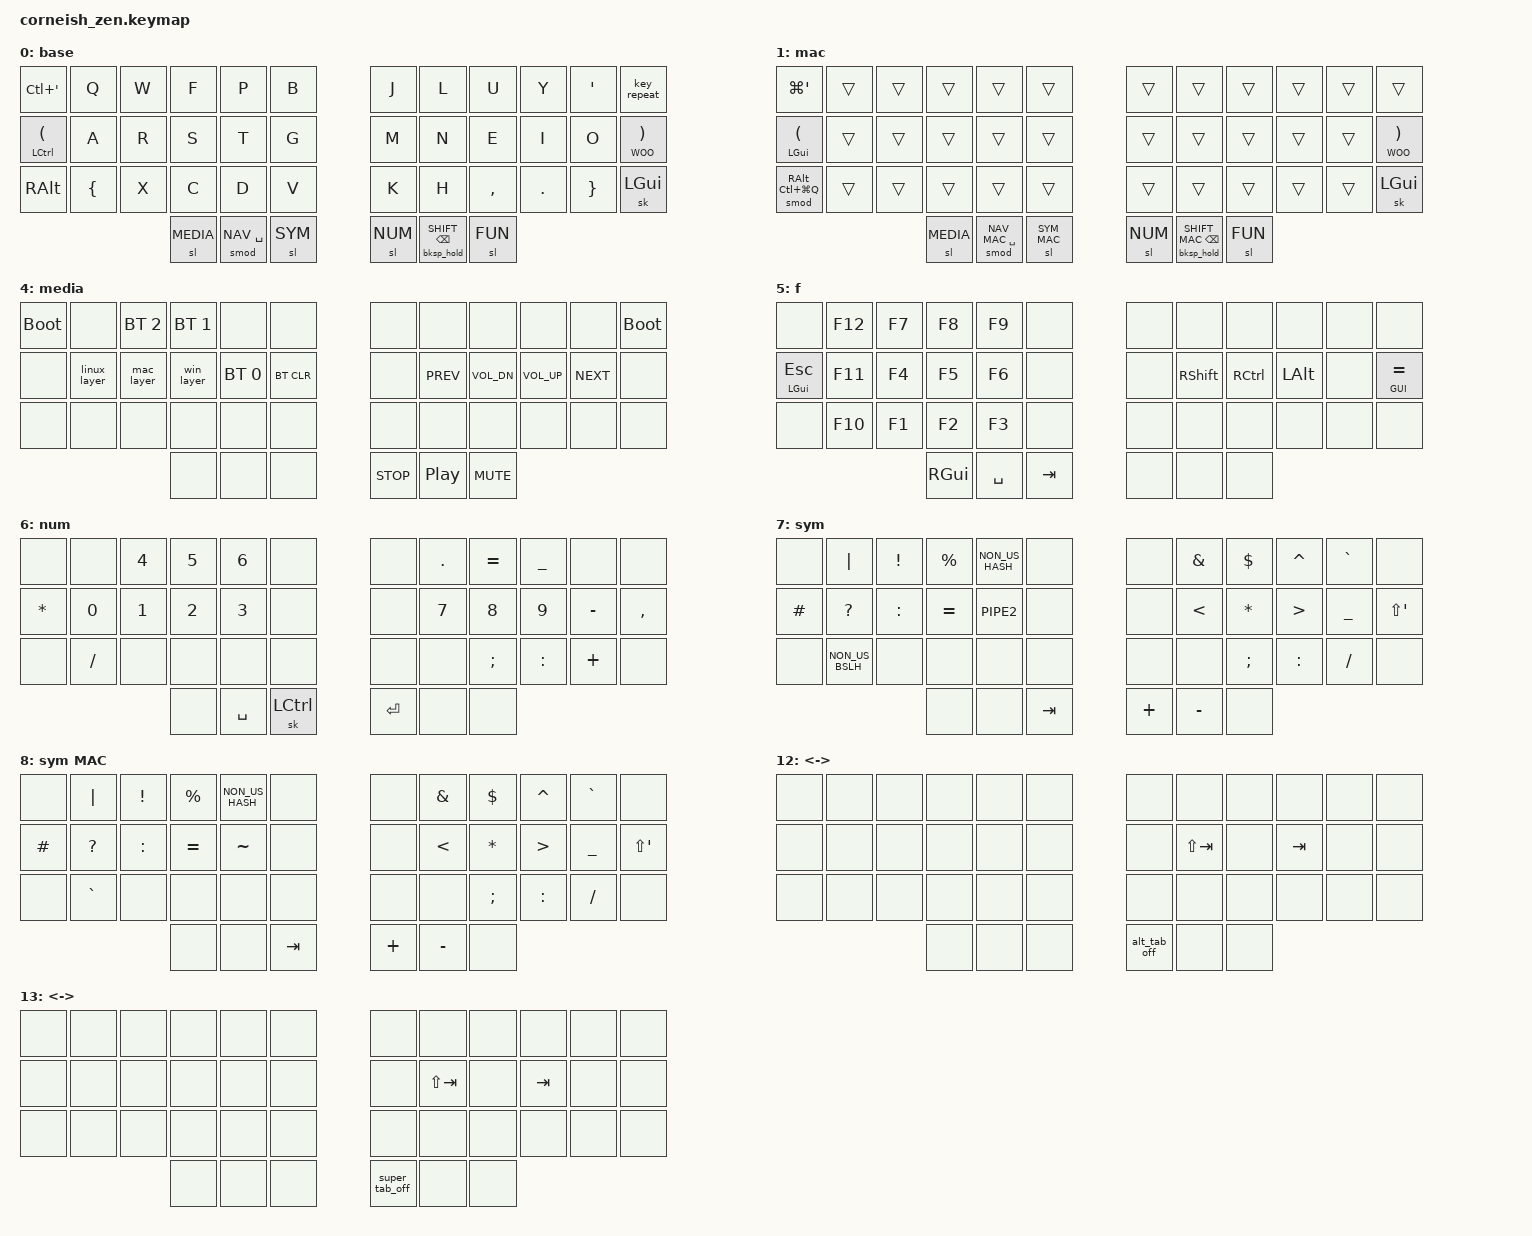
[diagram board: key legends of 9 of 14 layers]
/*
*
* Copyright (c) 2021 Darryl deHaan
* SPDX-License-Identifier: MIT
*
*/

#include <behaviors.dtsi>
#include <dt-bindings/zmk/keys.h>
#include <dt-bindings/zmk/bt.h>

#include "layers.dtsi"
#include "combos.dtsi"
#include "behaviors.dtsi"
#include "macros.dtsi"

/ {
    chosen {
        zmk,matrix_transform = &default_transform;
    };
};

#define HYPER LS(LC(LA(LGUI)))
#define MEH   LS(LC(LALT))
#define WOO   LC(LA(LGUI)) // I don't know what this is called

&caps_word {
    continue-list = <UNDERSCORE MINUS BACKSPACE N1 N2 N3 N4 N5 N6 N7 N8 N9 N0>;
};

/ {
    keymap {
        compatible = "zmk,keymap";

        base_layer {
            label = "base";
            bindings = <
// ╭─────────────────┬─────────────────┬─────────────────┬─────────────────┬─────────────────┬─────────────────╮   ╭─────────────────┬─────────────────┬─────────────────┬─────────────────┬─────────────────┬─────────────────╮
     &kp LC(SQT)       &kp Q           &kp W             &kp F             &kp P             &kp B                 &kp J             &kp L             &kp U             &kp Y             &kp SQT           &key_repeat
// ├─────────────────┼─────────────────┼─────────────────┼─────────────────┼─────────────────┼─────────────────┤   ├─────────────────┼─────────────────┼─────────────────┼─────────────────┼─────────────────┼─────────────────┤
     &hmod LCTRL LPAR  &kp A             &kp R             &kp S             &kp T             &kp G                 &kp M             &kp N             &kp E             &kp I             &kp O             &hmod WOO RPAR
// ├─────────────────┼─────────────────┼─────────────────┼─────────────────┼─────────────────┼─────────────────┤   ├─────────────────┼─────────────────┼─────────────────┼─────────────────┼─────────────────┼─────────────────┤
     &kp RALT          &kp LBRC          &kp X             &kp C             &kp D             &kp V                 &kp K             &kp H             &kp COMMA         &kp DOT           &kp RBRC          &sk LGUI
// ╰─────────────────┴─────────────────┴─────────────────┼─────────────────┼─────────────────┼─────────────────┤   ├─────────────────┼─────────────────┼─────────────────┼─────────────────┴─────────────────┴─────────────────╯
                                                           &sl MEDIA         &smod NAV SPACE   &sl SYM               &sl NUM        &bksp_hold SHIFT BKSP  &sl FUN
//                                                       ╰─────────────────┴─────────────────┴─────────────────╯   ╰─────────────────┴─────────────────┴─────────────────╯
            >;
        };
        
        base_layer_mac {
            label = "mac";
            bindings = <
// ╭─────────────────┬─────────────────┬─────────────────┬─────────────────┬─────────────────┬─────────────────╮   ╭─────────────────┬─────────────────┬─────────────────┬─────────────────┬─────────────────┬─────────────────╮
     &kp LG(SQT)       &trans          &trans            &trans            &trans            &trans                &trans            &trans            &trans            &trans            &trans            &trans
// ├─────────────────┼─────────────────┼─────────────────┼─────────────────┼─────────────────┼─────────────────┤   ├─────────────────┼─────────────────┼─────────────────┼─────────────────┼─────────────────┼─────────────────┤
     &hmod LGUI LPAR   &trans            &trans            &trans            &trans            &trans                &trans            &trans            &trans            &trans            &trans            &hmod WOO RPAR 
// ├─────────────────┼─────────────────┼─────────────────┼─────────────────┼─────────────────┼─────────────────┤   ├─────────────────┼─────────────────┼─────────────────┼─────────────────┼─────────────────┼─────────────────┤
 &smod RALT LC(LG(Q))  &trans            &trans            &trans            &trans            &trans                &trans            &trans            &trans            &trans            &trans            &sk LGUI
// ╰─────────────────┴─────────────────┴─────────────────┼─────────────────┼─────────────────┼─────────────────┤   ├─────────────────┼─────────────────┼─────────────────┼─────────────────┴─────────────────┴─────────────────╯
                                                           &sl MEDIA       &smod NAV_MAC SPACE  &sl SYM_MAC          &sl NUM      &bksp_hold SHIFT_MAC BKSP  &sl FUN
//                                                       ╰─────────────────┴─────────────────┴─────────────────╯   ╰─────────────────┴─────────────────┴─────────────────╯
            >;
        };
        
        shift_layer {
            label = "shift";
            bindings = <
// ╭─────────────────┬─────────────────┬─────────────────┬─────────────────┬─────────────────┬─────────────────╮   ╭─────────────────┬─────────────────┬─────────────────┬─────────────────┬─────────────────┬─────────────────╮
     &kp LC(LA(LG(SQT))) &kp LS(Q)         &kp LS(W)         &kp LS(F)         &kp LS(P)         &kp LS(B)             &kp LS(J)         &kp LS(L)         &kp LS(U)         &kp LS(Y)         &kp AT            &key_repeat
// ├─────────────────┼─────────────────┼─────────────────┼─────────────────┼─────────────────┼─────────────────┤   ├─────────────────┼─────────────────┼─────────────────┼─────────────────┼─────────────────┼─────────────────┤
     &kp GRAV          &kp LS(A)         &kp LS(R)         &kp LS(S)         &kp LS(T)         &kp LS(G)             &kp LS(M)         &kp LS(N)         &kp LS(E)         &kp LS(I)         &kp LS(O)         &kp EQUAL
// ├─────────────────┼─────────────────┼─────────────────┼─────────────────┼─────────────────┼─────────────────┤   ├─────────────────┼─────────────────┼─────────────────┼─────────────────┼─────────────────┼─────────────────┤
     &none             &kp LBKT          &kp LS(X)         &kp LS(C)         &kp LS(D)         &kp LS(V)             &kp LS(K)         &kp LS(H)         &kp SEMI          &kp COLON         &kp RBKT          &none
// ╰─────────────────┴─────────────────┴─────────────────┼─────────────────┼─────────────────┼─────────────────┤   ├─────────────────┼─────────────────┼─────────────────┼─────────────────┴─────────────────┴─────────────────╯
                                                           &sl MEDIA         &kp SPACE         &kp MINUS             &kp LS(RET)       &sk LSHIFT        &sl FUN
//                                                       ╰─────────────────┴─────────────────┴─────────────────╯   ╰─────────────────┴─────────────────┴─────────────────╯
            >;
        };

        shift_layer_mac {
            label = "shift MAC";
            bindings = <
// ╭─────────────────┬─────────────────┬─────────────────┬─────────────────┬─────────────────┬─────────────────╮   ╭─────────────────┬─────────────────┬─────────────────┬─────────────────┬─────────────────┬─────────────────╮
     &kp LC(LA(LG(SQT))) &kp LS(Q)         &kp LS(W)         &kp LS(F)         &kp LS(P)         &kp LS(B)             &kp LS(J)         &kp LS(L)         &kp LS(U)         &kp LS(Y)         &kp AT            &key_repeat
// ├─────────────────┼─────────────────┼─────────────────┼─────────────────┼─────────────────┼─────────────────┤   ├─────────────────┼─────────────────┼─────────────────┼─────────────────┼─────────────────┼─────────────────┤
     &kp NON_US_BSLH   &kp LS(A)         &kp LS(R)         &kp LS(S)         &kp LS(T)         &kp LS(G)             &kp LS(M)         &kp LS(N)         &kp LS(E)         &kp LS(I)         &kp LS(O)         &kp EQUAL
// ├─────────────────┼─────────────────┼─────────────────┼─────────────────┼─────────────────┼─────────────────┤   ├─────────────────┼─────────────────┼─────────────────┼─────────────────┼─────────────────┼─────────────────┤
     &none             &kp LBKT          &kp LS(X)         &kp LS(C)         &kp LS(D)         &kp LS(V)             &kp LS(K)         &kp LS(H)         &kp SEMI          &kp COLON         &kp RBKT          &none
// ╰─────────────────┴─────────────────┴─────────────────┼─────────────────┼─────────────────┼─────────────────┤   ├─────────────────┼─────────────────┼─────────────────┼─────────────────┴─────────────────┴─────────────────╯
                                                           &sl MEDIA         &kp SPACE         &kp MINUS             &kp LS(RET)       &sk LSHIFT        &sl FUN
//                                                       ╰─────────────────┴─────────────────┴─────────────────╯   ╰─────────────────┴─────────────────┴─────────────────╯
            >;
        };

        media_layer {
            label = "media";
            bindings = <
// ╭─────────────────┬─────────────────┬─────────────────┬─────────────────┬─────────────────┬─────────────────╮   ╭─────────────────┬─────────────────┬─────────────────┬─────────────────┬─────────────────┬─────────────────╮
     &bootloader       &none             &bt BT_SEL 2      &bt BT_SEL 1      &none             &none                 &none             &none             &none             &none             &none             &bootloader
// ├─────────────────┼─────────────────┼─────────────────┼─────────────────┼─────────────────┼─────────────────┤   ├─────────────────┼─────────────────┼─────────────────┼─────────────────┼─────────────────┼─────────────────┤
     &none             &linux_layer      &mac_layer        &win_layer        &bt BT_SEL 0      &bt BT_CLR            &none             &kp C_PREV        &kp C_VOL_DN      &kp C_VOL_UP      &kp C_NEXT        &none
// ├─────────────────┼─────────────────┼─────────────────┼─────────────────┼─────────────────┼─────────────────┤   ├─────────────────┼─────────────────┼─────────────────┼─────────────────┼─────────────────┼─────────────────┤
     &none             &none             &none             &none             &none             &none                 &none             &none             &none             &none             &none             &none
// ╰─────────────────┴─────────────────┴─────────────────┼─────────────────┼─────────────────┼─────────────────┤   ├─────────────────┼─────────────────┼─────────────────┼─────────────────┴─────────────────┴─────────────────╯
                                                           &none             &none             &none                 &kp C_STOP        &kp C_PLAY_PAUSE  &kp C_MUTE
//                                                       ╰─────────────────┴─────────────────┴─────────────────╯   ╰─────────────────┴─────────────────┴─────────────────╯
            >;
        };

        fun_layer {
            label = "f";
            bindings = <
// ╭─────────────────┬─────────────────┬─────────────────┬─────────────────┬─────────────────┬─────────────────╮   ╭─────────────────┬─────────────────┬─────────────────┬─────────────────┬─────────────────┬─────────────────╮
     &none             &kp F12           &kp F7            &kp F8            &kp F9            &none                 &none             &none             &none             &none             &none             &none
// ├─────────────────┼─────────────────┼─────────────────┼─────────────────┼─────────────────┼─────────────────┤   ├─────────────────┼─────────────────┼─────────────────┼─────────────────┼─────────────────┼─────────────────┤
     &mt LGUI ESC      &kp F11           &kp F4            &kp F5            &kp F6            &none                 &none             &kp RSHIFT        &kp RCTRL         &kp LALT          &none             &mt GUI EQUAL
// ├─────────────────┼─────────────────┼─────────────────┼─────────────────┼─────────────────┼─────────────────┤   ├─────────────────┼─────────────────┼─────────────────┼─────────────────┼─────────────────┼─────────────────┤
     &none             &kp F10           &kp F1            &kp F2            &kp F3            &none                 &none             &none             &none             &none             &none             &none
// ╰─────────────────┴─────────────────┴─────────────────┼─────────────────┼─────────────────┼─────────────────┤   ├─────────────────┼─────────────────┼─────────────────┼─────────────────┴─────────────────┴─────────────────╯
                                                           &kp RGUI          &kp SPACE         &kp TAB               &none             &none             &none
//                                                       ╰─────────────────┴─────────────────┴─────────────────╯   ╰─────────────────┴─────────────────┴─────────────────╯
            >;
        };


        num {
            label = "num";
            bindings = <
// ╭─────────────────┬─────────────────┬─────────────────┬─────────────────┬─────────────────┬─────────────────╮   ╭─────────────────┬─────────────────┬─────────────────┬─────────────────┬─────────────────┬─────────────────╮
     &none             &none             &kp N4            &kp N5            &kp N6            &none                 &none             &kp DOT           &kp EQUAL         &kp UNDERSCORE    &none             &none
// ├─────────────────┼─────────────────┼─────────────────┼─────────────────┼─────────────────┼─────────────────┤   ├─────────────────┼─────────────────┼─────────────────┼─────────────────┼─────────────────┼─────────────────┤
     &kp ASTRK         &kp N0            &kp N1            &kp N2            &kp N3            &none                 &none             &kp N7            &kp N8            &kp N9            &kp MINUS         &kp COMMA
// ├─────────────────┼─────────────────┼─────────────────┼─────────────────┼─────────────────┼─────────────────┤   ├─────────────────┼─────────────────┼─────────────────┼─────────────────┼─────────────────┼─────────────────┤
     &none             &kp FSLH          &none             &none             &none             &none                 &none             &none             &kp SEMI          &kp COLON         &kp PLUS          &none
// ╰─────────────────┴─────────────────┴─────────────────┼─────────────────┼─────────────────┼─────────────────┤   ├─────────────────┼─────────────────┼─────────────────┼─────────────────┴─────────────────┴─────────────────╯
                                                           &none             &kp SPACE         &sk LCTRL             &kp RET           &none             &none
//                                                       ╰─────────────────┴─────────────────┴─────────────────╯   ╰─────────────────┴─────────────────┴─────────────────╯
            >;
        };

        sym {
            label = "sym";
            bindings = <
// ╭─────────────────┬─────────────────┬─────────────────┬─────────────────┬─────────────────┬─────────────────╮   ╭─────────────────┬─────────────────┬─────────────────┬─────────────────┬─────────────────┬─────────────────╮
     &none             &kp PIPE          &kp EXCL          &kp PERCENT       &kp NON_US_HASH   &none                 &none             &kp AMPS          &kp DOLLAR        &kp CARET         &kp GRAV          &none
// ├─────────────────┼─────────────────┼─────────────────┼─────────────────┼─────────────────┼─────────────────┤   ├─────────────────┼─────────────────┼─────────────────┼─────────────────┼─────────────────┼─────────────────┤
     &kp HASH          &kp QUESTION      &kp COLON         &kp EQUAL         &kp PIPE2         &none                 &none             &kp LT            &kp ASTRK         &kp GT            &kp UNDERSCORE    &kp LS(SQT)
// ├─────────────────┼─────────────────┼─────────────────┼─────────────────┼─────────────────┼─────────────────┤   ├─────────────────┼─────────────────┼─────────────────┼─────────────────┼─────────────────┼─────────────────┤
     &none             &kp NON_US_BSLH   &none             &none             &none             &none                 &none             &none             &kp SEMI          &kp COLON         &kp FSLH          &none
// ╰─────────────────┴─────────────────┴─────────────────┼─────────────────┼─────────────────┼─────────────────┤   ├─────────────────┼─────────────────┼─────────────────┼─────────────────┴─────────────────┴─────────────────╯
                                                           &none             &none             &kp TAB               &kp PLUS          &kp MINUS         &none
//                                                       ╰─────────────────┴─────────────────┴─────────────────╯   ╰─────────────────┴─────────────────┴─────────────────╯
            >;
        };

        sym_mac {
            label = "sym MAC";
            bindings = <
// ╭─────────────────┬─────────────────┬─────────────────┬─────────────────┬─────────────────┬─────────────────╮   ╭─────────────────┬─────────────────┬─────────────────┬─────────────────┬─────────────────┬─────────────────╮
     &none             &kp PIPE          &kp EXCL          &kp PERCENT       &kp NON_US_HASH   &none                 &none             &kp AMPS          &kp DOLLAR        &kp CARET         &kp GRAV          &none
// ├─────────────────┼─────────────────┼─────────────────┼─────────────────┼─────────────────┼─────────────────┤   ├─────────────────┼─────────────────┼─────────────────┼─────────────────┼─────────────────┼─────────────────┤
     &kp HASH          &kp QUESTION      &kp COLON         &kp EQUAL         &kp TILDE         &none                 &none             &kp LT            &kp ASTRK         &kp GT            &kp UNDERSCORE    &kp LS(SQT)
// ├─────────────────┼─────────────────┼─────────────────┼─────────────────┼─────────────────┼─────────────────┤   ├─────────────────┼─────────────────┼─────────────────┼─────────────────┼─────────────────┼─────────────────┤
     &none             &kp GRAV          &none             &none             &none             &none                 &none             &none             &kp SEMI          &kp COLON         &kp FSLH          &none
// ╰─────────────────┴─────────────────┴─────────────────┼─────────────────┼─────────────────┼─────────────────┤   ├─────────────────┼─────────────────┼─────────────────┼─────────────────┴─────────────────┴─────────────────╯
                                                           &none             &none             &kp TAB               &kp PLUS          &kp MINUS         &none
//                                                       ╰─────────────────┴─────────────────┴─────────────────╯   ╰─────────────────┴─────────────────┴─────────────────╯
            >;
        };

        nav {
            label = "nav";
            bindings = <
// ╭─────────────────┬─────────────────┬─────────────────┬─────────────────┬─────────────────┬─────────────────╮   ╭─────────────────┬─────────────────┬─────────────────┬─────────────────┬─────────────────┬─────────────────╮
     &none             &none             &none             &kp HOME          &kp END           &none                 &none             &kp F12           &kp UP            &kp LC(F12)       &none             &none
// ├─────────────────┼─────────────────┼─────────────────┼─────────────────┼─────────────────┼─────────────────┤   ├─────────────────┼─────────────────┼─────────────────┼─────────────────┼─────────────────┼─────────────────┤
     &none             &kp LC(TAB)       &kp LA(TAB)       &kp PG_UP         &kp PG_DN         &none                 &none             &kp LEFT          &kp DOWN          &kp RIGHT         &kp DEL           &none
// ├─────────────────┼─────────────────┼─────────────────┼─────────────────┼─────────────────┼─────────────────┤   ├─────────────────┼─────────────────┼─────────────────┼─────────────────┼─────────────────┼─────────────────┤
     &none             &none             &none             &none             &none             &none                 &none             &none             &none             &none             &kp DEL           &none
// ╰─────────────────┴─────────────────┴─────────────────┼─────────────────┼─────────────────┼─────────────────┤   ├─────────────────┼─────────────────┼─────────────────┼─────────────────┴─────────────────┴─────────────────╯
                                                           &none             &none             &none                 &alt_tab_on       &kp LG(LC(LA(SPACE)))     &caps_word
//                                                       ╰─────────────────┴─────────────────┴─────────────────╯   ╰─────────────────┴─────────────────┴─────────────────╯
            >;
        };
        
        nav_mac {
            label = "nav MAC";
            bindings = <
// ╭─────────────────┬─────────────────┬─────────────────┬─────────────────┬─────────────────┬─────────────────╮   ╭─────────────────┬─────────────────┬─────────────────┬─────────────────┬─────────────────┬─────────────────╮
     &none             &none             &none             &kp HOME          &kp END           &none                 &none             &kp F12           &kp UP            &kp LG(F12)       &none             &none
// ├─────────────────┼─────────────────┼─────────────────┼─────────────────┼─────────────────┼─────────────────┤   ├─────────────────┼─────────────────┼─────────────────┼─────────────────┼─────────────────┼─────────────────┤
     &none           &kp LG(NON_US_BSLH) &kp LG(TAB)       &kp PG_UP         &kp PG_DN         &none                 &none             &kp LEFT          &kp DOWN          &kp RIGHT         &kp DEL           &none
// ├─────────────────┼─────────────────┼─────────────────┼─────────────────┼─────────────────┼─────────────────┤   ├─────────────────┼─────────────────┼─────────────────┼─────────────────┼─────────────────┼─────────────────┤
     &none             &none             &none             &none             &none             &none                 &none             &none             &none             &none             &kp DEL           &none
// ╰─────────────────┴─────────────────┴─────────────────┼─────────────────┼─────────────────┼─────────────────┤   ├─────────────────┼─────────────────┼─────────────────┼─────────────────┴─────────────────┴─────────────────╯
                                                           &none             &none             &none                 &super_tab_on     &kp LG(LC(LA(SPACE)))     &caps_word
//                                                       ╰─────────────────┴─────────────────┴─────────────────╯   ╰─────────────────┴─────────────────┴─────────────────╯
            >;
        };
        
        fn {
            label = "fn";
            bindings = <
// ╭─────────────────┬─────────────────┬─────────────────┬─────────────────┬─────────────────┬─────────────────╮   ╭─────────────────┬─────────────────┬─────────────────┬─────────────────┬─────────────────┬─────────────────╮
     &none             &none             &kp F5            &kp F8            &none             &none                 &none             &none             &none             &none             &none             &none
// ├─────────────────┼─────────────────┼─────────────────┼─────────────────┼─────────────────┼─────────────────┤   ├─────────────────┼─────────────────┼─────────────────┼─────────────────┼─────────────────┼─────────────────┤
     &none             &none             &kp F10           &kp F2            &kp F12           &none                 &none             &kp LC(LA(LG(0))) &kp LC(LA(LG(1))) &kp LC(LA(LG(3))) &none             &none
// ├─────────────────┼─────────────────┼─────────────────┼─────────────────┼─────────────────┼─────────────────┤   ├─────────────────┼─────────────────┼─────────────────┼─────────────────┼─────────────────┼─────────────────┤
     &none             &none             &none             &none             &none             &none                 &none             &none             &none             &none             &none             &none
// ╰─────────────────┴─────────────────┴─────────────────┼─────────────────┼─────────────────┼─────────────────┤   ├─────────────────┼─────────────────┼─────────────────┼─────────────────┴─────────────────┴─────────────────╯
                                                           &none             &none             &none                 &none             &none             &none
//                                                       ╰─────────────────┴─────────────────┴─────────────────╯   ╰─────────────────┴─────────────────┴─────────────────╯
            >;
        };

        alt_tab {
            label = "<->";
            bindings = <
// ╭─────────────────┬─────────────────┬─────────────────┬─────────────────┬─────────────────┬─────────────────╮   ╭─────────────────┬─────────────────┬─────────────────┬─────────────────┬─────────────────┬─────────────────╮
     &none             &none             &none             &none             &none             &none                 &none             &none             &none             &none             &none             &none
// ├─────────────────┼─────────────────┼─────────────────┼─────────────────┼─────────────────┼─────────────────┤   ├─────────────────┼─────────────────┼─────────────────┼─────────────────┼─────────────────┼─────────────────┤
     &none             &none             &none             &none             &none             &none                 &none             &kp LS(TAB)       &none             &kp TAB           &none             &none
// ├─────────────────┼─────────────────┼─────────────────┼─────────────────┼─────────────────┼─────────────────┤   ├─────────────────┼─────────────────┼─────────────────┼─────────────────┼─────────────────┼─────────────────┤
     &none             &none             &none             &none             &none             &none                 &none             &none             &none             &none             &none             &none
// ╰─────────────────┴─────────────────┴─────────────────┼─────────────────┼─────────────────┼─────────────────┤   ├─────────────────┼─────────────────┼─────────────────┼─────────────────┴─────────────────┴─────────────────╯
                                                           &none             &none             &none                 &alt_tab_off      &none             &none
//                                                       ╰─────────────────┴─────────────────┴─────────────────╯   ╰─────────────────┴─────────────────┴─────────────────╯
            >;
        };

        super_tab {
            label = "<->";
            bindings = <
// ╭─────────────────┬─────────────────┬─────────────────┬─────────────────┬─────────────────┬─────────────────╮   ╭─────────────────┬─────────────────┬─────────────────┬─────────────────┬─────────────────┬─────────────────╮
     &none             &none             &none             &none             &none             &none                 &none             &none             &none             &none             &none             &none
// ├─────────────────┼─────────────────┼─────────────────┼─────────────────┼─────────────────┼─────────────────┤   ├─────────────────┼─────────────────┼─────────────────┼─────────────────┼─────────────────┼─────────────────┤
     &none             &none             &none             &none             &none             &none                 &none             &kp LS(TAB)       &none             &kp TAB           &none             &none
// ├─────────────────┼─────────────────┼─────────────────┼─────────────────┼─────────────────┼─────────────────┤   ├─────────────────┼─────────────────┼─────────────────┼─────────────────┼─────────────────┼─────────────────┤
     &none             &none             &none             &none             &none             &none                 &none             &none             &none             &none             &none             &none
// ╰─────────────────┴─────────────────┴─────────────────┼─────────────────┼─────────────────┼─────────────────┤   ├─────────────────┼─────────────────┼─────────────────┼─────────────────┴─────────────────┴─────────────────╯
                                                           &none             &none             &none                 &super_tab_off    &none             &none
//                                                       ╰─────────────────┴─────────────────┴─────────────────╯   ╰─────────────────┴─────────────────┴─────────────────╯
            >;
        };       
    };
};
